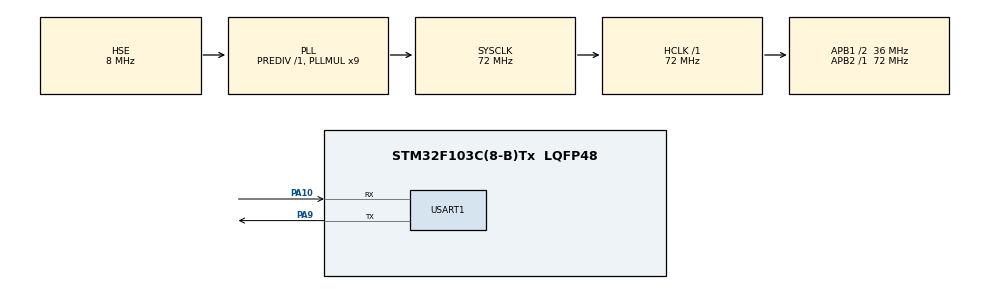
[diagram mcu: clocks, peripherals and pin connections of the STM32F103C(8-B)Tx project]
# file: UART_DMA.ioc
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Mcu.Family=STM32F1
RCC.PLLSourceVirtual=RCC_PLLSOURCE_HSE
NVIC.DMA1_Channel5_IRQn=true\:0\:0\:false\:false\:true\:false\:true
PD1-OSC_OUT.Mode=HSE-External-Oscillator
Dma.USART1_RX.0.PeriphDataAlignment=DMA_PDATAALIGN_BYTE
PA10.Mode=Asynchronous
PD0-OSC_IN.Signal=RCC_OSC_IN
RCC.APB1CLKDivider=RCC_HCLK_DIV2
RCC.SYSCLKSource=RCC_SYSCLKSOURCE_PLLCLK
ProjectManager.StackSize=0x400
PD1-OSC_OUT.Signal=RCC_OSC_OUT
PA13.Signal=SYS_JTMS-SWDIO
PA9.Mode=Asynchronous
ProjectManager.TargetToolchain=STM32CubeIDE
Dma.USART1_RX.0.Direction=DMA_PERIPH_TO_MEMORY
RCC.HCLKFreq_Value=72000000
RCC.APB2TimFreq_Value=72000000
PA9.Signal=USART1_TX
RCC.USBFreq_Value=72000000
RCC.AHBFreq_Value=72000000
Dma.USART1_RX.0.PeriphInc=DMA_PINC_DISABLE
Dma.USART1_RX.0.Priority=DMA_PRIORITY_LOW
PD0-OSC_IN.Mode=HSE-External-Oscillator
board=custom
RCC.PLLMUL=RCC_PLL_MUL9
RCC.APB2Freq_Value=72000000
PA14.Mode=Serial_Wire
Dma.USART1_RX.0.MemDataAlignment=DMA_MDATAALIGN_BYTE
Dma.USART1_RX.0.MemInc=DMA_MINC_ENABLE
PA13.Mode=Serial_Wire
Mcu.Name=STM32F103C(8-B)Tx
RCC.SYSCLKFreq_VALUE=72000000
Mcu.Package=LQFP48
USART1.VirtualMode=VM_ASYNC
PA10.Signal=USART1_RX
PA14.Signal=SYS_JTCK-SWCLK
ProjectManager.HeapSize=0x200
NVIC.PriorityGroup=NVIC_PRIORITYGROUP_4
RCC.APB1TimFreq_Value=72000000
Dma.USART1_RX.0.Mode=DMA_NORMAL
Dma.Request0=USART1_RX
RCC.APB1Freq_Value=36000000
Dma.USART1_RX.0.Instance=DMA1_Channel5

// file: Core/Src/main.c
/* USER CODE BEGIN Header */
/**
  ******************************************************************************
  * @file           : main.c
  * @brief          : Main program body
  ******************************************************************************
  * @attention
  *
  * <h2><center>&copy; Copyright (c) 2021 STMicroelectronics.
  * All rights reserved.</center></h2>
  *
  * This software component is licensed by ST under BSD 3-Clause license,
  * the "License"; You may not use this file except in compliance with the
  * License. You may obtain a copy of the License at:
  *                        opensource.org/licenses/BSD-3-Clause
  *
  ******************************************************************************
  */
/* USER CODE END Header */
#include "main.h"

UART_HandleTypeDef huart1;
DMA_HandleTypeDef hdma_usart1_rx;

/* USER CODE BEGIN PV */
uint8_t UART1_rxBuffer[12] = {0};

/* USER CODE END PV */

void SystemClock_Config(void);
static void MX_GPIO_Init(void);
static void MX_DMA_Init(void);
static void MX_USART1_UART_Init(void);

int main(void)
{

  /* MCU Configuration--------------------------------------------------------*/

  /* Reset of all peripherals, Initializes the Flash interface and the Systick. */
  HAL_Init();

  /* Configure the system clock */
  SystemClock_Config();

  /* Initialize all configured peripherals */
  MX_GPIO_Init();
  MX_DMA_Init();
  MX_USART1_UART_Init();
  /* USER CODE BEGIN 2 */
  HAL_UART_Receive_DMA (&huart1, UART1_rxBuffer, 12);
  /* USER CODE END 2 */

  /* Infinite loop */
  while (1)
  {

  }
}

void SystemClock_Config(void)
{
  RCC_OscInitTypeDef RCC_OscInitStruct = {0};
  RCC_ClkInitTypeDef RCC_ClkInitStruct = {0};

  /** Initializes the RCC Oscillators according to the specified parameters
  * in the RCC_OscInitTypeDef structure.
  */
  RCC_OscInitStruct.OscillatorType = RCC_OSCILLATORTYPE_HSE;
  RCC_OscInitStruct.HSEState = RCC_HSE_ON;
  RCC_OscInitStruct.HSEPredivValue = RCC_HSE_PREDIV_DIV1;
  RCC_OscInitStruct.HSIState = RCC_HSI_ON;
  RCC_OscInitStruct.PLL.PLLState = RCC_PLL_ON;
  RCC_OscInitStruct.PLL.PLLSource = RCC_PLLSOURCE_HSE;
  RCC_OscInitStruct.PLL.PLLMUL = RCC_PLL_MUL9;
  if (HAL_RCC_OscConfig(&RCC_OscInitStruct) != HAL_OK)
  {
    Error_Handler();
  }
  /** Initializes the CPU, AHB and APB buses clocks
  */
  RCC_ClkInitStruct.ClockType = RCC_CLOCKTYPE_HCLK|RCC_CLOCKTYPE_SYSCLK
                              |RCC_CLOCKTYPE_PCLK1|RCC_CLOCKTYPE_PCLK2;
  RCC_ClkInitStruct.SYSCLKSource = RCC_SYSCLKSOURCE_PLLCLK;
  RCC_ClkInitStruct.AHBCLKDivider = RCC_SYSCLK_DIV1;
  RCC_ClkInitStruct.APB1CLKDivider = RCC_HCLK_DIV2;
  RCC_ClkInitStruct.APB2CLKDivider = RCC_HCLK_DIV1;

  if (HAL_RCC_ClockConfig(&RCC_ClkInitStruct, FLASH_LATENCY_2) != HAL_OK)
  {
    Error_Handler();
  }
}

static void MX_USART1_UART_Init(void)
{

  huart1.Instance = USART1;
  huart1.Init.BaudRate = 115200;
  huart1.Init.WordLength = UART_WORDLENGTH_8B;
  huart1.Init.StopBits = UART_STOPBITS_1;
  huart1.Init.Parity = UART_PARITY_NONE;
  huart1.Init.Mode = UART_MODE_TX_RX;
  huart1.Init.HwFlowCtl = UART_HWCONTROL_NONE;
  huart1.Init.OverSampling = UART_OVERSAMPLING_16;
  if (HAL_UART_Init(&huart1) != HAL_OK)
  {
    Error_Handler();
  }

}

static void MX_DMA_Init(void)
{

  /* DMA controller clock enable */
  __HAL_RCC_DMA1_CLK_ENABLE();

  /* DMA interrupt init */
  /* DMA1_Channel5_IRQn interrupt configuration */
  HAL_NVIC_SetPriority(DMA1_Channel5_IRQn, 0, 0);
  HAL_NVIC_EnableIRQ(DMA1_Channel5_IRQn);

}

static void MX_GPIO_Init(void)
{

  /* GPIO Ports Clock Enable */
  __HAL_RCC_GPIOD_CLK_ENABLE();
  __HAL_RCC_GPIOA_CLK_ENABLE();

}

/* USER CODE BEGIN 4 */
void HAL_UART_RxCpltCallback(UART_HandleTypeDef *huart)
{
    HAL_UART_Transmit(&huart1, UART1_rxBuffer, 12, 100);
    HAL_UART_Receive_DMA(&huart1, UART1_rxBuffer, 12);
}
/* USER CODE END 4 */

void Error_Handler(void)
{
  __disable_irq();
  while (1)
  {
  }
}

/************************ (C) COPYRIGHT STMicroelectronics *****END OF FILE****/
